VERSION ""

NS_ :

BS_:

BU_:

BO_ 3221225472 VECTOR__INDEPENDENT_SIG_MSG: 0 Vector__XXX
 SG_ channel1_mV : 16|12@1+ (1,0) [0|0] "" Vector__XXX
 SG_ channel2_mV : 28|12@1+ (1,0) [0|0] "" Vector__XXX
 SG_ channel4_mV : 52|12@1+ (1,0) [0|0] "" Vector__XXX
 SG_ channel3_mV : 40|12@1+ (1,0) [0|0] "" Vector__XXX
 SG_ boardVersion : 0|4@1+ (1,0) [0|0] "" Vector__XXX
 SG_ firmwareVersion : 4|4@1+ (1,0) [0|0] "" Vector__XXX

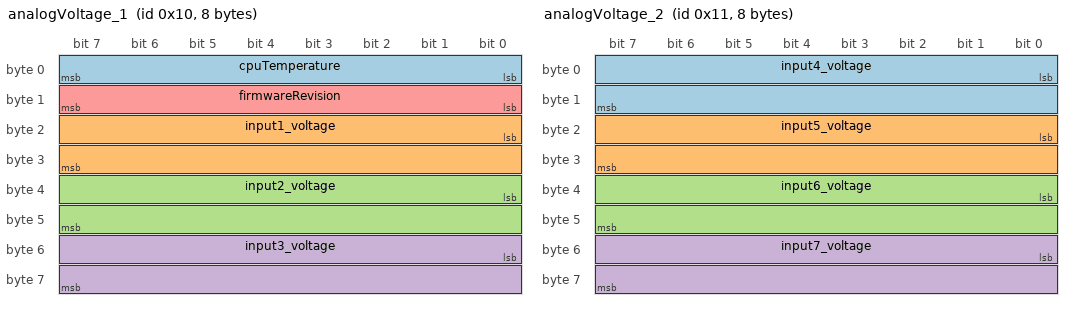
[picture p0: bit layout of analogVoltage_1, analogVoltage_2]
BO_ 16 analogVoltage_1: 8 Vector__XXX
 SG_ cpuTemperature : 0|8@1- (1,0) [0|0] "" Vector__XXX
 SG_ input1_voltage : 16|16@1+ (0.001,0) [0|5] "V" Vector__XXX
 SG_ input2_voltage : 32|16@1+ (0.001,0) [0|0] "V" Vector__XXX
 SG_ input3_voltage : 48|16@1+ (0.001,0) [0|0] "V" Vector__XXX
 SG_ firmwareRevision : 8|8@1+ (1,0) [0|0] "" Vector__XXX

BO_ 17 analogVoltage_2: 8 Vector__XXX
 SG_ input4_voltage : 0|16@1+ (0.001,0) [0|5] "V" Vector__XXX
 SG_ input5_voltage : 16|16@1+ (0.001,0.004883) [0|5] "V" Vector__XXX
 SG_ input6_voltage : 32|16@1+ (0.001,0) [0|5] "V" Vector__XXX
 SG_ input7_voltage : 48|16@1+ (0.001,0) [0|5] "V" Vector__XXX

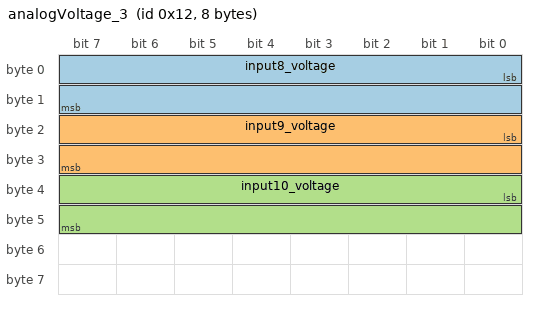
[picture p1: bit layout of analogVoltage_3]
BO_ 18 analogVoltage_3: 8 Vector__XXX
 SG_ input8_voltage : 0|16@1+ (0.001,0) [0|5] "V" Vector__XXX
 SG_ input9_voltage : 16|16@1+ (0.001,0) [0|5] "V" Vector__XXX
 SG_ input10_voltage : 32|16@1+ (0.001,0) [0|5] "V" Vector__XXX
